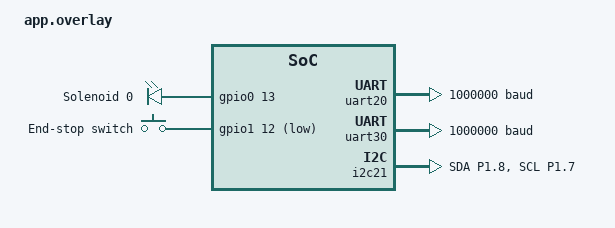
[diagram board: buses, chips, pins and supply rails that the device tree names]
/*
 * Device tree overlay for DM860E stepper motor driver and PCA9685
 * KDAA UART 1M Baud with HW Flow Control
 */

/ {
	chosen {
		zephyr,console = &uart30;
		zephyr,shell-uart = &uart30;
	};

	solenoids {
		compatible = "gpio-leds";
		solenoid0: solenoid_0 {
			/* Physical Solenoid on Pin P0.13 (Fallback if not PCA) */
			gpios = <&gpio0 13 GPIO_ACTIVE_HIGH>;
			label = "Solenoid 0";
		};
	};

	dtsendstop {
		compatible = "gpio-keys";
		endstop_switch: endstop_switch {
			gpios = <&gpio1 12 (GPIO_ACTIVE_LOW | GPIO_PULL_UP)>;
			label = "End-stop switch";
		};
	};

	aliases {
		solenoid = &solenoid0;
		dtsendstop = &endstop_switch;
	};
};

&gpio1 {
    status = "okay";
};

&uart20 {
	status = "okay";
	current-speed = <1000000>;
	hw-flow-control;
};

&uart30 {
	status = "okay";
	current-speed = <1000000>;
};

&pinctrl {
	i2c21_default: i2c21_default {
		group1 {
			psels = <NRF_PSEL(TWIM_SDA, 1, 8)>,
					<NRF_PSEL(TWIM_SCL, 1, 7)>;
		};
	};

	i2c21_sleep: i2c21_sleep {
		group1 {
			psels = <NRF_PSEL(TWIM_SDA, 1, 8)>,
					<NRF_PSEL(TWIM_SCL, 1, 7)>;
			low-power-enable;
		};
	};
};

&i2c21 {
	status = "okay";
	pinctrl-0 = <&i2c21_default>;
	pinctrl-1 = <&i2c21_sleep>;
	pinctrl-names = "default", "sleep";
};
